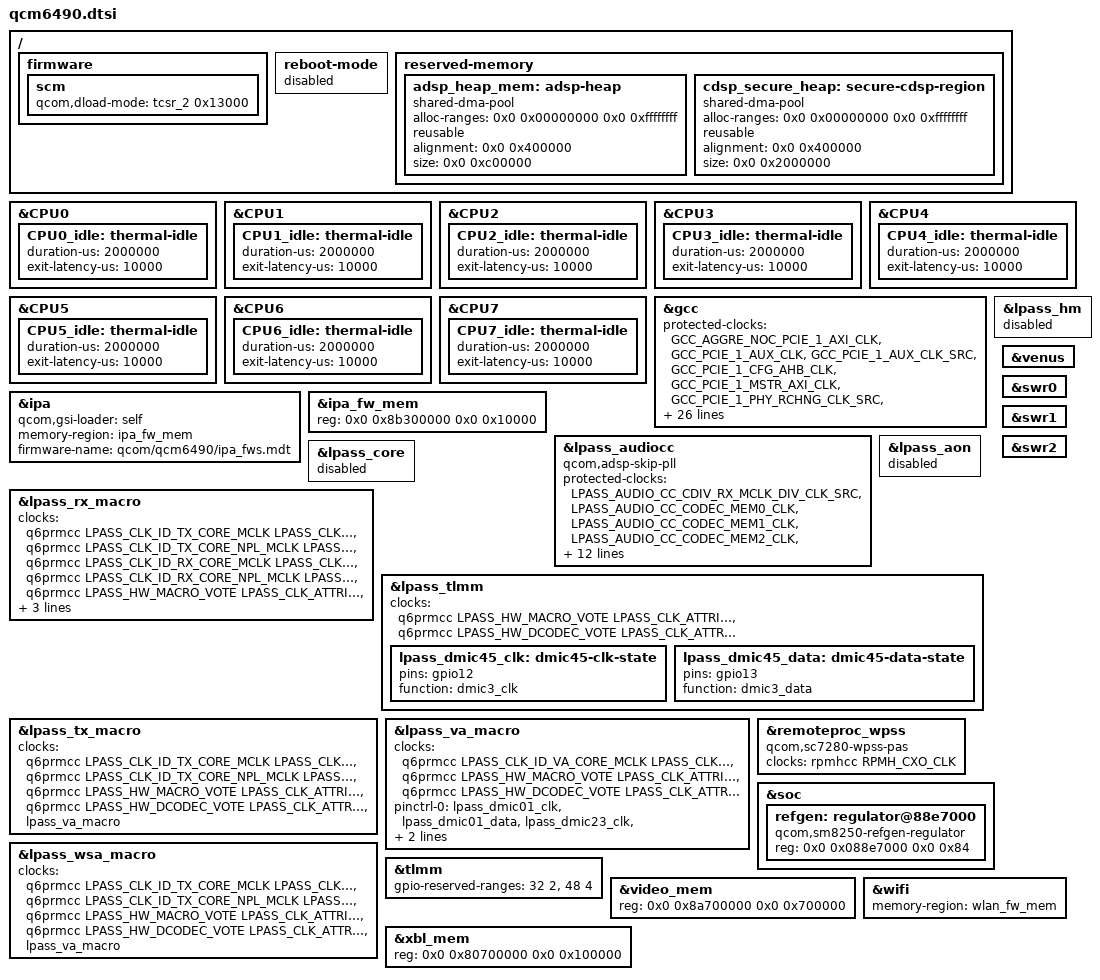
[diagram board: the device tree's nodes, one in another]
// SPDX-License-Identifier: BSD-3-Clause
/*
 * Copyright (c) 2023-2025 Qualcomm Innovation Center, Inc. All rights reserved.
 */

#include <dt-bindings/soc/qcom,gpr.h>
#include <dt-bindings/sound/qcom,q6afe.h>
#include "sc7280.dtsi"

/{
	firmware {
		scm {
			qcom,dload-mode = <&tcsr_2 0x13000>;
		};
	};

	reboot-mode {
		status = "disabled";
	};

	reserved-memory {
		adsp_heap_mem: adsp-heap {
			compatible = "shared-dma-pool";
			alloc-ranges = <0x0 0x00000000 0x0 0xffffffff>;
			reusable;
			alignment = <0x0 0x400000>;
			size = <0x0 0xc00000>;
		};

		cdsp_secure_heap: secure-cdsp-region { /* Secure DSP */
			compatible = "shared-dma-pool";
			alloc-ranges = <0x0 0x00000000 0x0 0xffffffff>;
			reusable;
			alignment = <0x0 0x400000>;
			size = <0x0 0x2000000>;
		};
	};
};

&CPU0 {
	CPU0_idle: thermal-idle {
		#cooling-cells = <2>;
		duration-us = <2000000>;
		exit-latency-us = <10000>;
	};
};

&CPU1 {
	CPU1_idle: thermal-idle {
		#cooling-cells = <2>;
		duration-us = <2000000>;
		exit-latency-us = <10000>;
	};
};

&CPU2 {
	CPU2_idle: thermal-idle {
		#cooling-cells = <2>;
		duration-us = <2000000>;
		exit-latency-us = <10000>;
	};
};

&CPU3 {
	CPU3_idle: thermal-idle {
		#cooling-cells = <2>;
		duration-us = <2000000>;
		exit-latency-us = <10000>;
	};
};

&CPU4 {
	CPU4_idle: thermal-idle {
		#cooling-cells = <2>;
		duration-us = <2000000>;
		exit-latency-us = <10000>;
	};
};

&CPU5 {
	CPU5_idle: thermal-idle {
		#cooling-cells = <2>;
		duration-us = <2000000>;
		exit-latency-us = <10000>;
	};
};

&CPU6 {
	CPU6_idle: thermal-idle {
		#cooling-cells = <2>;
		duration-us = <2000000>;
		exit-latency-us = <10000>;
	};
};

&CPU7 {
	CPU7_idle: thermal-idle {
		#cooling-cells = <2>;
		duration-us = <2000000>;
		exit-latency-us = <10000>;
	};
};

&gcc {
	protected-clocks = <GCC_AGGRE_NOC_PCIE_1_AXI_CLK> ,<GCC_PCIE_1_AUX_CLK>,
			<GCC_PCIE_1_AUX_CLK_SRC>, <GCC_PCIE_1_CFG_AHB_CLK>,
			<GCC_PCIE_1_MSTR_AXI_CLK>, <GCC_PCIE_1_PHY_RCHNG_CLK_SRC>,
			<GCC_PCIE_1_PIPE_CLK>, <GCC_PCIE_1_PIPE_CLK_SRC>,
			<GCC_PCIE_1_SLV_AXI_CLK>, <GCC_PCIE_1_SLV_Q2A_AXI_CLK>,
			<GCC_QSPI_CNOC_PERIPH_AHB_CLK>, <GCC_QSPI_CORE_CLK>,
			<GCC_QSPI_CORE_CLK_SRC>,<GCC_USB30_SEC_MASTER_CLK>,
			<GCC_USB30_SEC_MASTER_CLK_SRC>, <GCC_USB30_SEC_MOCK_UTMI_CLK>,
			<GCC_USB30_SEC_MOCK_UTMI_CLK_SRC>,
			<GCC_USB30_SEC_MOCK_UTMI_POSTDIV_CLK_SRC>, <GCC_USB30_SEC_SLEEP_CLK>,
			<GCC_USB3_SEC_PHY_AUX_CLK>, <GCC_USB3_SEC_PHY_AUX_CLK_SRC>,
			<GCC_USB3_SEC_PHY_COM_AUX_CLK>, <GCC_USB3_SEC_PHY_PIPE_CLK>,
			<GCC_USB3_SEC_PHY_PIPE_CLK_SRC>, <GCC_CFG_NOC_LPASS_CLK>,
			<GCC_MSS_GPLL0_MAIN_DIV_CLK_SRC>, <GCC_MSS_CFG_AHB_CLK>,
			<GCC_MSS_OFFLINE_AXI_CLK>, <GCC_MSS_SNOC_AXI_CLK>,
			<GCC_MSS_Q6_MEMNOC_AXI_CLK>, <GCC_MSS_Q6SS_BOOT_CLK_SRC>,
			<GCC_SEC_CTRL_CLK_SRC>, <GCC_WPSS_AHB_CLK>,
			<GCC_WPSS_AHB_BDG_MST_CLK>, <GCC_WPSS_RSCP_CLK>;
};

&ipa {
	qcom,gsi-loader = "self";
	memory-region = <&ipa_fw_mem>;
	firmware-name = "qcom/qcm6490/ipa_fws.mdt";
	status = "okay";
};

&ipa_fw_mem {
	reg = <0x0 0x8b300000 0x0 0x10000>;
};

&lpass_audiocc {
	qcom,adsp-skip-pll;
	protected-clocks = <LPASS_AUDIO_CC_CDIV_RX_MCLK_DIV_CLK_SRC>,
		<LPASS_AUDIO_CC_CODEC_MEM0_CLK>, <LPASS_AUDIO_CC_CODEC_MEM1_CLK>,
		<LPASS_AUDIO_CC_CODEC_MEM2_CLK>, <LPASS_AUDIO_CC_CODEC_MEM_CLK>,
		<LPASS_AUDIO_CC_EXT_MCLK0_CLK>, <LPASS_AUDIO_CC_EXT_MCLK0_CLK_SRC>,
		<LPASS_AUDIO_CC_EXT_MCLK1_CLK>, <LPASS_AUDIO_CC_EXT_MCLK1_CLK_SRC>,
		<LPASS_AUDIO_CC_PLL>, <LPASS_AUDIO_CC_PLL_OUT_AUX2>,
		<LPASS_AUDIO_CC_PLL_OUT_AUX2_DIV_CLK_SRC>,
		<LPASS_AUDIO_CC_PLL_OUT_MAIN_DIV_CLK_SRC>,
		<LPASS_AUDIO_CC_RX_MCLK_2X_CLK>, <LPASS_AUDIO_CC_RX_MCLK_CLK>,
		<LPASS_AUDIO_CC_RX_MCLK_CLK_SRC>;
	/delete-property/ power-domains;
};

&lpass_aon {
	status = "disabled";
};

&lpass_core {
	status = "disabled";
};

&lpass_hm {
	status = "disabled";
};

&lpass_rx_macro {
	/delete-property/ power-domains;
	/delete-property/ power-domain-names;
	clocks = <&q6prmcc LPASS_CLK_ID_TX_CORE_MCLK LPASS_CLK_ATTRIBUTE_COUPLE_NO>,
		 <&q6prmcc LPASS_CLK_ID_TX_CORE_NPL_MCLK  LPASS_CLK_ATTRIBUTE_COUPLE_NO>,
		 <&q6prmcc LPASS_CLK_ID_RX_CORE_MCLK  LPASS_CLK_ATTRIBUTE_COUPLE_NO>,
		 <&q6prmcc LPASS_CLK_ID_RX_CORE_NPL_MCLK  LPASS_CLK_ATTRIBUTE_COUPLE_NO>,
		 <&q6prmcc LPASS_HW_MACRO_VOTE LPASS_CLK_ATTRIBUTE_COUPLE_NO>,
		 <&q6prmcc LPASS_HW_DCODEC_VOTE LPASS_CLK_ATTRIBUTE_COUPLE_NO>,
		 <&lpass_va_macro>;
	clock-names = "mclk", "npl", "rx-mclk", "rx-npl", "macro", "dcodec", "fsgen";

	qcom,rx_mclk_mode_muxsel = <0x033240D8>;

	status = "okay";
};

&lpass_tlmm {
	clocks = <&q6prmcc LPASS_HW_MACRO_VOTE LPASS_CLK_ATTRIBUTE_COUPLE_NO>,
		 <&q6prmcc LPASS_HW_DCODEC_VOTE LPASS_CLK_ATTRIBUTE_COUPLE_NO>;
	clock-names = "core", "audio";

	lpass_dmic45_clk: dmic45-clk-state {
		pins = "gpio12";
		function = "dmic3_clk";
	};

	lpass_dmic45_data: dmic45-data-state {
		pins = "gpio13";
		function = "dmic3_data";
	};
};

&lpass_tx_macro {
	/delete-property/ power-domains;
	/delete-property/ power-domain-names;
	clocks = <&q6prmcc LPASS_CLK_ID_TX_CORE_MCLK LPASS_CLK_ATTRIBUTE_COUPLE_NO>,
		 <&q6prmcc LPASS_CLK_ID_TX_CORE_NPL_MCLK  LPASS_CLK_ATTRIBUTE_COUPLE_NO>,
		 <&q6prmcc LPASS_HW_MACRO_VOTE LPASS_CLK_ATTRIBUTE_COUPLE_NO>,
		 <&q6prmcc LPASS_HW_DCODEC_VOTE LPASS_CLK_ATTRIBUTE_COUPLE_NO>,
		 <&lpass_va_macro>;
	clock-names = "mclk", "npl", "macro", "dcodec", "fsgen";

	status = "okay";
};

&lpass_va_macro {
	/delete-property/ power-domains;
	/delete-property/ power-domain-names;
	clocks = <&q6prmcc LPASS_CLK_ID_VA_CORE_MCLK LPASS_CLK_ATTRIBUTE_COUPLE_NO>,
		 <&q6prmcc LPASS_HW_MACRO_VOTE LPASS_CLK_ATTRIBUTE_COUPLE_NO>,
		 <&q6prmcc LPASS_HW_DCODEC_VOTE LPASS_CLK_ATTRIBUTE_COUPLE_NO>;
	clock-names = "mclk", "macro", "dcodec";

	pinctrl-names = "default";
	pinctrl-0 = <&lpass_dmic01_clk>, <&lpass_dmic01_data>,
		    <&lpass_dmic23_clk>, <&lpass_dmic23_data>,
		    <&lpass_dmic45_clk>, <&lpass_dmic45_data>;

	status = "okay";
};

&lpass_wsa_macro {
	/delete-property/ power-domains;
	/delete-property/ power-domain-names;
	clocks = <&q6prmcc LPASS_CLK_ID_TX_CORE_MCLK LPASS_CLK_ATTRIBUTE_COUPLE_NO>,
		 <&q6prmcc LPASS_CLK_ID_TX_CORE_NPL_MCLK LPASS_CLK_ATTRIBUTE_COUPLE_NO>,
		 <&q6prmcc LPASS_HW_MACRO_VOTE LPASS_CLK_ATTRIBUTE_COUPLE_NO>,
		 <&q6prmcc LPASS_HW_DCODEC_VOTE LPASS_CLK_ATTRIBUTE_COUPLE_NO>,
		 <&lpass_va_macro>;
	clock-names = "mclk", "npl", "macro", "dcodec", "fsgen";

	status = "okay";
};

&remoteproc_wpss {
	compatible = "qcom,sc7280-wpss-pas";

	clocks = <&rpmhcc RPMH_CXO_CLK>;
	clock-names = "xo";

	/delete-property/ qcom,halt-regs;
	/delete-property/ resets;
	/delete-property/ reset-names;
};

&soc {
	refgen:regulator@88e7000 {
		compatible = "qcom,sm8250-refgen-regulator";
		reg = <0x0 0x088e7000 0x0 0x84>;
	};

};

&venus {
	status = "okay";
};

&swr0 {
	status = "okay";
};

&swr1 {
	status = "okay";
};

&swr2 {
	status = "okay";
};

&tlmm {
	gpio-reserved-ranges = <32 2>, <48 4>;
};

&video_mem {
	reg = <0x0 0x8a700000 0x0 0x700000>;
};

&wifi {
	memory-region = <&wlan_fw_mem>;
};

&xbl_mem {
	reg = <0x0 0x80700000 0x0 0x100000>;
};
